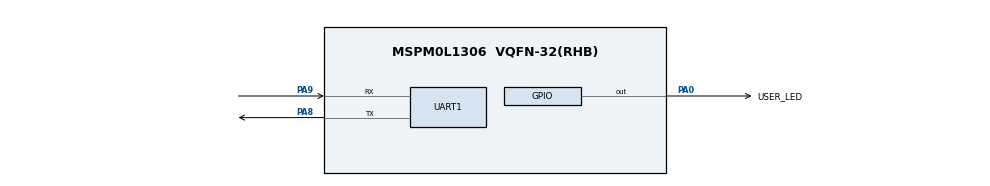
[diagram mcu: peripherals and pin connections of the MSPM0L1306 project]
/**
 * Three ways, DriverLib, LP-MSPM0L1306: ADC0 channel 9 on PA15 (the onboard thermistor) against the
 * internal 2.5 V reference, UART0 at 115200 on PA8/PA9 (backchannel), LED1 on PA0 (open drain, J2 and J10 2:3).
 * 32 MHz SYSOSC, TI's default clock tree.
 */
//@cliArgs --device "MSPM0L130X" --package "VQFN-32(RHB)" --part "Default"
//@v2CliArgs --device "MSPM0L1306" --package "VQFN-32(RHB)"
// @cliArgs --board /ti/boards/LP_MSPM0L1306 --rtos nortos

const Board  = scripting.addModule("/ti/driverlib/Board");
const SYSCTL = scripting.addModule("/ti/driverlib/SYSCTL");
const ADC12  = scripting.addModule("/ti/driverlib/ADC12", {}, false);
const ADC121 = ADC12.addInstance();
const GPIO   = scripting.addModule("/ti/driverlib/GPIO", {}, false);
const GPIO1  = GPIO.addInstance();
const UART   = scripting.addModule("/ti/driverlib/UART", {}, false);
const UART1  = UART.addInstance();
const VREF   = scripting.addModule("/ti/driverlib/VREF");

ADC121.$name                       = "ADC12_0";
ADC121.sampClkSrc                  = "DL_ADC12_CLOCK_SYSOSC";
ADC121.sampClkDiv                  = "DL_ADC12_CLOCK_DIVIDE_8";
ADC121.adcMem0chansel              = "DL_ADC12_INPUT_CHAN_9";
ADC121.sampleTime0                 = "125 us";
ADC121.adcMem0vref                 = "VREF";
ADC121.adcMem0vrefDependencySelect = "DL_ADC12_REFERENCE_VOLTAGE_INTREF";
ADC121.powerDownMode               = "DL_ADC12_POWER_DOWN_MODE_MANUAL";
ADC121.peripheral.$assign          = "ADC0";
ADC121.peripheral.adcPin9.$assign  = "PA15";

GPIO1.$name                          = "GPIO_LEDS";
GPIO1.port                           = "PORTA";
GPIO1.associatedPins[0].$name        = "USER_LED";
GPIO1.associatedPins[0].assignedPin  = "0";
GPIO1.associatedPins[0].pin.$assign  = "PA0";

UART1.$name                    = "UART_0";
UART1.peripheral.$assign       = "UART0";
UART1.peripheral.rxPin.$assign = "PA9";
UART1.peripheral.txPin.$assign = "PA8";
UART1.targetBaudRate           = 115200;

VREF.basicIntVolt         = "DL_VREF_BUFCONFIG_OUTPUT_2_5V";
VREF.advClockConfigEnable = true;
VREF.advClkSrc            = "DL_VREF_CLOCK_BUSCLK";
VREF.peripheral.$assign   = "VREF";

SYSCTL.clockTreeEn = true;
